# DMA_208.0_inst6 register map
Vendor: Texas Instruments
Peripheral module from a debugger description file (folder msp430).
Registers are 16-bit, access not given, no defined reset value unless marked. A register's access mark holds for its fields unless they carry their own. Offsets are as the file gives them; lines under a group give offsets from that group; [hi:lo] are bit positions; {n}, {i} and the like mark numbered series; 'fields as' and 'values as' point back to an identical list; <NAME> marks a mode.

## DMA
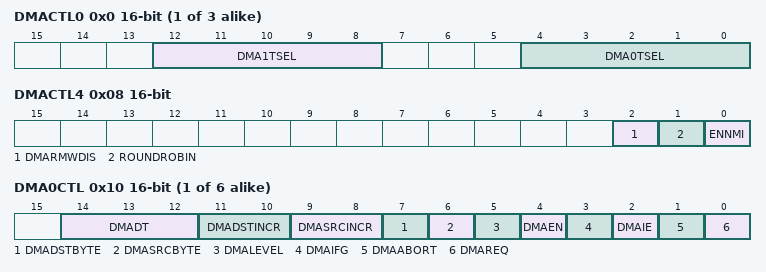
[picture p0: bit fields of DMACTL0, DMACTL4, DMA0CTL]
{0x0+2i} DMACTL{i} rw (i=0..2) — DMA Control {i}
  [12:8] DMA{2i+1}TSEL — DMA trigger select
    {v}=DMA{2i+1}TRIG{v} (v=0..31)
  [4:0] DMA{2i}TSEL — DMA trigger select
    {v}=DMA{2i}TRIG{v} (v=0..31)
0x08 DMACTL4 rw — DMA Control 4
  [2] DMARMWDIS — Read-modify-write disable
    0=DMA transfers can occur during read-modify-write CPU operations; 1=DMA transfers inhibited during read-modify-write CPU operations
  [1] ROUNDROBIN
    0=DMA channel priority is DMA0-DMA1-DMA2 - ... - DMA7; 1=DMA channel priority changes with each transfer
  [0] ENNMI — Enable NMI
    0=NMI does not interrupt DMA transfer; 1=NMI interrupts a DMA transfer
0x0E DMAIV ro — DMA Interrupt Vector
  [15:0] DMAIV — DMA interrupt vector value
    0=NONE (No interrupt pending); 2=DMA0IFG (Interrupt Source: DMA channel 0; Interrupt Flag: DMA0IFG; Interrupt Priority: Highest); 4=DMA1IFG (Interrupt Source: DMA channel 1; Interrupt Flag: DMA1IFG); 6=DMA2IFG (Interrupt Source: DMA channel 2; Interrupt Flag: DMA2IFG); 8=DMA3IFG (Interrupt Source: DMA channel 3; Interrupt Flag: DMA3IFG); 10=DMA4IFG (Interrupt Source: DMA channel 4; Interrupt Flag: DMA4IFG); 12=DMA5IFG (Interrupt Source: DMA channel 5; Interrupt Flag: DMA5IFG); 14=DMA6IFG (Interrupt Source: DMA channel 6; Interrupt Flag: DMA6IFG); 16=DMA7IFG (Interrupt Source: DMA channel 7; Interrupt Flag: DMA7IFG; Interrupt Priority: Lowest)
{0x10+0x10*i} DMA{i}CTL rw (i=0..5) — DMA Channel {i} Control
  [14:12] DMADT — DMA transfer mode
    0=Single transfer; 1=Block transfer; 2=Burst-block transfer; 3=Burst-block transfer; 4=Repeated single transfer; 5=Repeated block transfer; 6=Repeated burst-block transfer; 7=Repeated burst-block transfer
  [11:10] DMADSTINCR — DMA destination increment
    0=Destination address is unchanged; 1=Destination address is unchanged; 2=Destination address is decremented; 3=Destination address is incremented
  [9:8] DMASRCINCR — DMA source increment
    0=Source address is unchanged; 1=Source address is unchanged; 2=Source address is decremented; 3=Source address is incremented
  [7] DMADSTBYTE — DMA destination byte
    0=WORD; 1=BYTE
  [6] DMASRCBYTE — DMA source byte
    0=WORD; 1=BYTE
  [5] DMALEVEL
    0=EDGE (Edge sensitive (rising edge)); 1=LEVEL (Level sensitive (high level))
  [4] DMAEN — DMA enable
    0=DISABLE (Disabled); 1=ENABLE (Enabled)
  [3] DMAIFG — DMA interrupt flag
    0=No interrupt pending; 1=Interrupt pending
  [2] DMAIE — DMA interrupt enable
    0=DISABLE (Disabled); 1=ENABLE (Enabled)
  [1] DMAABORT
    0=DMA transfer not interrupted; 1=DMA transfer interrupted by NMI
  [0] DMAREQ — DMA request
    0=No DMA start; 1=Start DMA
{0x12+0x10*i} DMA{i}SA 20-bit (i=0..5) — DMA Channel {i} Source Address
{0x16+0x10*i} DMA{i}DA 20-bit (i=0..5) — DMA Channel {i} Destination Address
{0x1A+0x10*i} DMA{i}SZ (i=0..5) — DMA Channel {i} Transfer Size
